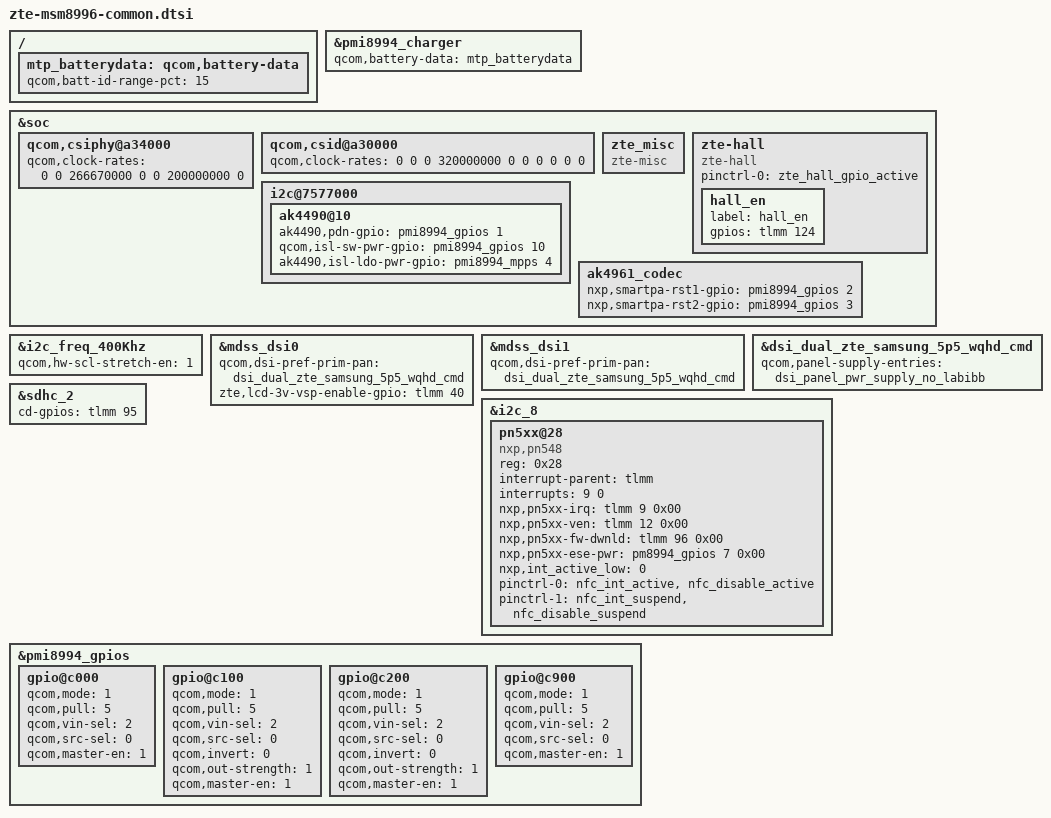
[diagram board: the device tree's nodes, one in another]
/* Copyright (c) 2015, The Linux Foundation. All rights reserved.
 *
 * This program is free software; you can redistribute it and/or modify
 * it under the terms of the GNU General Public License version 2 and
 * only version 2 as published by the Free Software Foundation.
 *
 * This program is distributed in the hope that it will be useful,
 * but WITHOUT ANY WARRANTY; without even the implied warranty of
 * MERCHANTABILITY or FITNESS FOR A PARTICULAR PURPOSE.  See the
 * GNU General Public License for more details.
 */

#include "zte-camera-sensor-mtp.dtsi"
#include "zte-usb-type-c.dtsi"

// Battery
/ {
	mtp_batterydata: qcom,battery-data {
		qcom,batt-id-range-pct = <15>;
		#include "zte_p996a01_3250mah.dtsi"
	};
};

&pmi8994_charger {
	qcom,battery-data = <&mtp_batterydata>;
};

// Camera

&soc {
	qcom,csiphy@a34000 {
		qcom,clock-rates = <0 0 266670000 0 0 200000000 0>;
	};

	qcom,csid@a30000  {
		qcom,clock-rates = <0 0 0 320000000 0 0 0 0 0 0>;
	};
};

&i2c_freq_400Khz {
	qcom,hw-scl-stretch-en = <1>;
};

// Display
&mdss_dsi0 {
	qcom,dsi-pref-prim-pan = <&dsi_dual_zte_samsung_5p5_wqhd_cmd>;
	zte,lcd-3v-vsp-enable-gpio = <&tlmm 40 0>;
	/delete-property/ qcom,platform-bklight-en-gpio;
};

&mdss_dsi1 {
	qcom,dsi-pref-prim-pan = <&dsi_dual_zte_samsung_5p5_wqhd_cmd>;
	/delete-property/ qcom,platform-bklight-en-gpio;
};

&dsi_dual_zte_samsung_5p5_wqhd_cmd {
	qcom,panel-supply-entries = <&dsi_panel_pwr_supply_no_labibb>;
};

// HAll
&soc {
    zte_misc {
        compatible = "zte-misc";
    };

    zte-hall {
        compatible = "zte-hall";
        pinctrl-names = "zte_hall_gpio_active";
        pinctrl-0 = <&zte_hall_gpio_active>;
        hall_en{
            label = "hall_en";
            gpios = <&tlmm 124 0x0>;
        };
    };
};


//NFC
&i2c_8 {
	/delete-node/ nq@28;
	pn5xx@28{
		compatible = "nxp,pn548";
		reg = <0x28>;
		interrupt-parent = <&tlmm>;
		interrupts = <9 0>;
		nxp,pn5xx-irq = <&tlmm 9 0x00>;
		nxp,pn5xx-ven = <&tlmm 12 0x00>;
		nxp,pn5xx-fw-dwnld = <&tlmm 96 0x00>;
		nxp,pn5xx-ese-pwr = <&pm8994_gpios 7 0x00>;
		//nxp,pn5xx-swp2-pwr = <&tlmm129 0x00>;
		nxp,int_active_low = <0>;
		/*nxp,pn5xx-clkreq = <&pm8994_gpios 2 0x00>;
		nxp,clk-src = "BBCLK2";
		interrupt-names = "nfc_irq";*/
		pinctrl-names = "nfc_active","nfc_suspend";
		pinctrl-0 = <&nfc_int_active &nfc_disable_active>;
		pinctrl-1 = <&nfc_int_suspend &nfc_disable_suspend>;
		/*clocks = <&clock_gcc clk_bb_clk2_pin>;
		clock-names = "bb_clk2";*/
	};
};

// Storage
&sdhc_2 {
	cd-gpios = <&tlmm 95 0x0>;
};

// Sound
&pmi8994_gpios {
	gpio@c000 {	/* GPIO 1  AKM4490 */
		qcom,mode = <1>;	/* DIGITAL OUT */
		qcom,pull = <5>;	/* No Pull */
		qcom,vin-sel = <2>;	/* 1.8 */
		qcom,src-sel = <0>;	/* CONSTANT */
		qcom,master-en = <1>;	/* ENABLE GPIO */
		status = "okay";
	};

	gpio@c100 {	/* GPIO 2  SPKR_SD_N */
		qcom,mode = <1>;	/* DIGITAL OUT */
		qcom,pull = <5>;	/* No Pull */
		qcom,vin-sel = <2>;	/* 1.8 */
		qcom,src-sel = <0>;	/* CONSTANT */
		qcom,invert = <0>;		/* Output low initially */
		qcom,out-strength = <1>;  /* QPNP_PIN_OUT_STRENGTH_LOW */
		qcom,master-en = <1>;	/* ENABLE GPIO */
		status = "okay";
	};

	gpio@c200 {	/* GPIO 3 SPKR_SD_N */
		qcom,mode = <1>;	/* DIGITAL OUT */
		qcom,pull = <5>;	/* No Pull */
		qcom,vin-sel = <2>;	/* 1.8 */
		qcom,src-sel = <0>;	/* CONSTANT */
		qcom,invert = <0>;		/* Output low initially */
		qcom,out-strength = <1>;  /* QPNP_PIN_OUT_STRENGTH_LOW */
		qcom,master-en = <1>;	/* ENABLE GPIO */
		status = "okay";
	};

	gpio@c900 { /* GPIO 10 - HPH_EN1 */
		qcom,mode = <1>;
		qcom,pull = <5>;
		qcom,vin-sel = <2>;
		qcom,src-sel = <0>;
		qcom,master-en = <1>;
		status = "okay";
	};
};

&soc {
	i2c@7577000 { /* BLSP1 QUP3 */
		ak4490@10 {
                        ak4490,pdn-gpio = <&pmi8994_gpios 1 0>;
                        qcom,isl-sw-pwr-gpio = <&pmi8994_gpios 10 0>;
                        ak4490,isl-ldo-pwr-gpio = <&pmi8994_mpps 4 0>;
                };
	};

	ak4961_codec {
		nxp,smartpa-rst1-gpio = <&pmi8994_gpios 2 0>;
		nxp,smartpa-rst2-gpio = <&pmi8994_gpios 3 0>;
	};

	/delete-node/ sound-9335;
};
